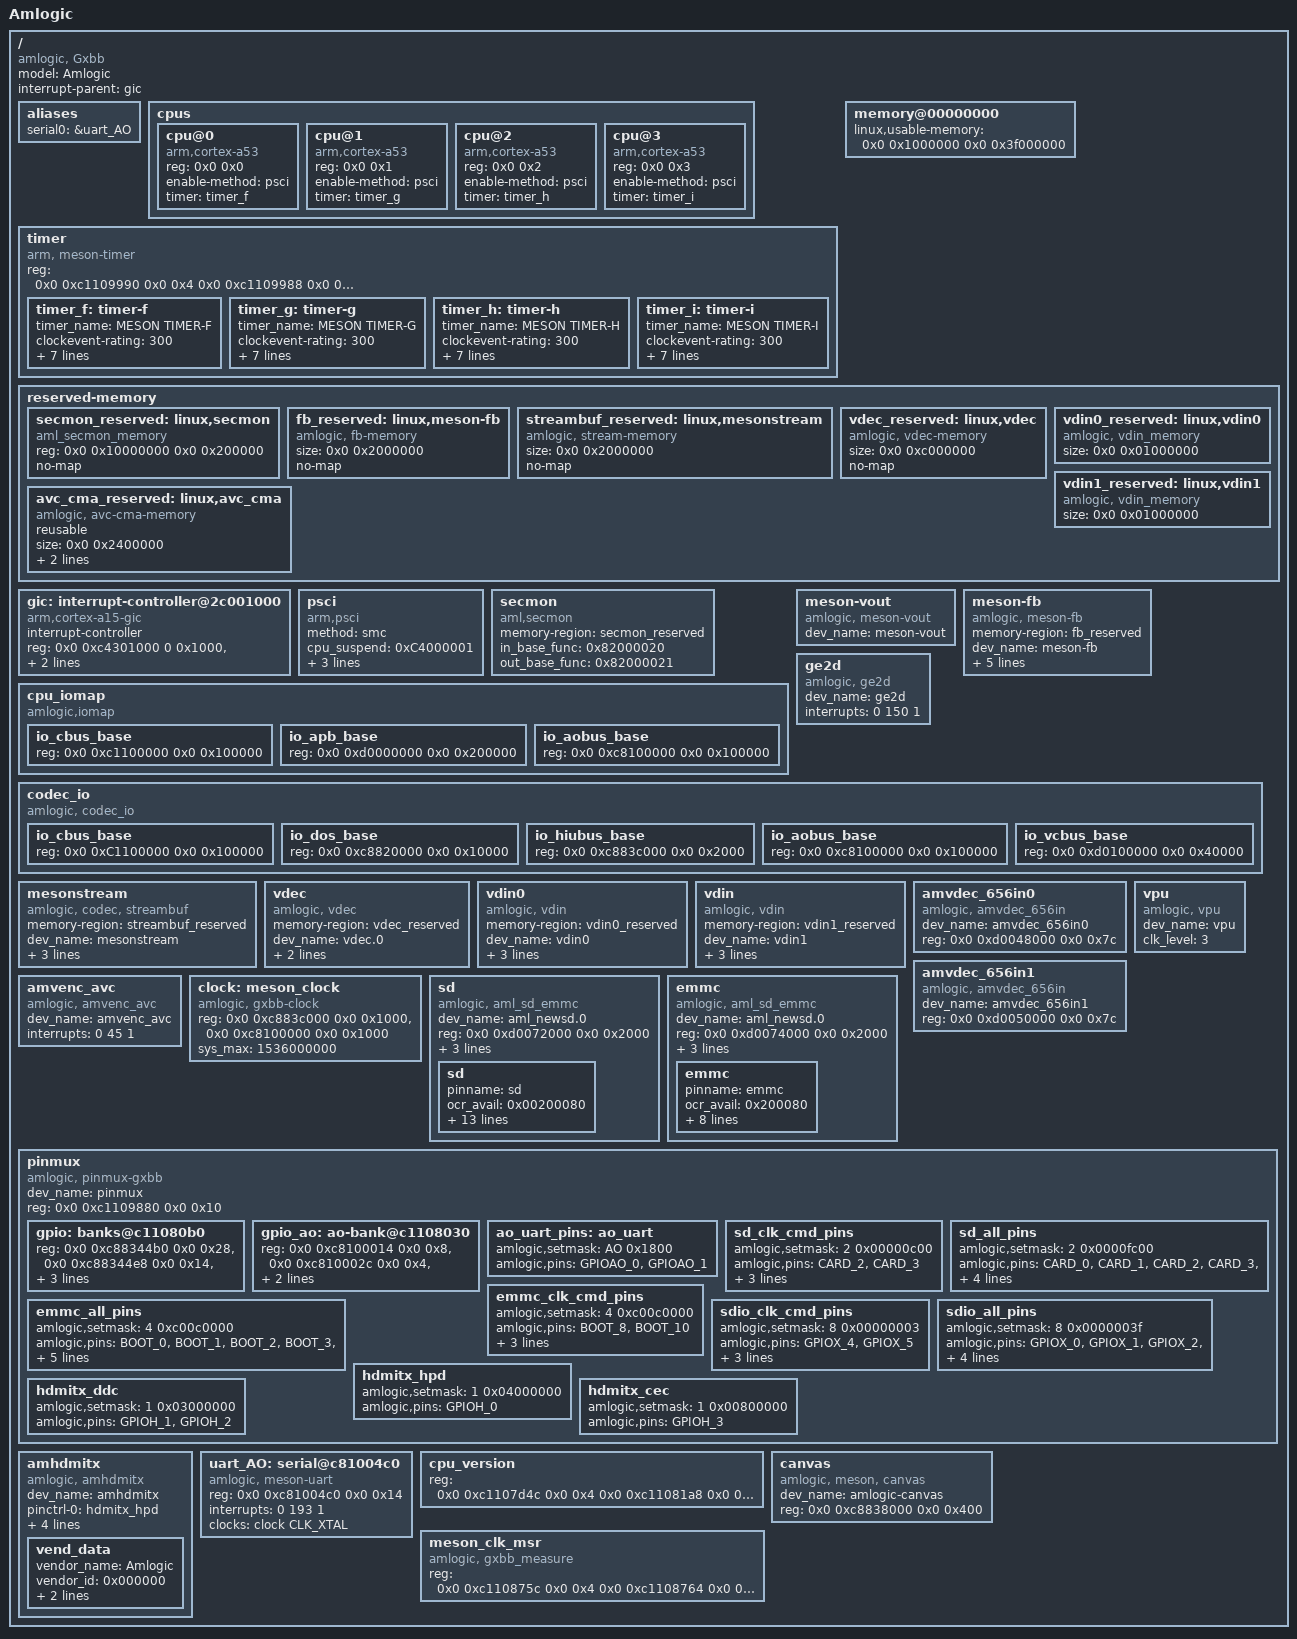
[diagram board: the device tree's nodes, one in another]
/*
 * Amlogic Ltd. GXBaby Plaform
 *
 */

/dts-v1/;

#include <dt-bindings/interrupt-controller/arm-gic.h>
#include <dt-bindings/clock/gxbb.h>
#include <dt-bindings/gpio/gxbb.h>
#include <dt-bindings/gpio/gpio.h>
#include <dt-bindings/reset/aml_gxbb.h>
/ {
	model = "Amlogic";
	compatible = "amlogic, Gxbb";
	interrupt-parent = <&gic>;
	#address-cells = <2>;
	#size-cells = <2>;

	aliases {
		serial0 = &uart_AO;
	};


	cpus {
		#address-cells = <2>;
		#size-cells = <0>;

		cpu@0 {
			device_type = "cpu";
			compatible = "arm,cortex-a53","arm,armv8";
			reg = <0x0 0x0>;
			enable-method = "psci";
			timer=<&timer_f>;
		};

		cpu@1 {
			device_type = "cpu";
			compatible = "arm,cortex-a53","arm,armv8";
			reg = <0x0 0x1>;
			enable-method = "psci";
			timer=<&timer_g>;
		};
		cpu@2 {
			device_type = "cpu";
			compatible = "arm,cortex-a53","arm,armv8";
			reg = <0x0 0x2>;
			enable-method = "psci";
			timer=<&timer_h>;
		};

		cpu@3 {
			device_type = "cpu";
			compatible = "arm,cortex-a53","arm,armv8";
			reg = <0x0 0x3>;
			enable-method = "psci";
			timer=<&timer_i>;
		};


	};
	timer{
		compatible = "arm, meson-timer";
		#address-cells = <2>;
		#size-cells = <2>;
		ranges;
		reg=   <0x0 0xc1109990 0x0 0x4 0x0 0xc1109988 0x0 0x4>;
		timer_f:timer-f{
			timer_name="MESON TIMER-F";
			clockevent-rating=<300>;
			clockevent-shift=<20>;
			clockevent-features=<0x03>;
			interrupts = <0 60 0>;
			bit_enable=<16>;
			bit_mode=<12>;
			bit_resolution=<0>;
			reg=   <0x0 0xc1109994 0x0 0x4>;
		};
		timer_g:timer-g{
			timer_name="MESON TIMER-G";
			clockevent-rating=<300>;
			clockevent-shift=<20>;
			clockevent-features=<0x03>;
			interrupts = <0 61 0>;
			bit_enable=<17>;
			bit_mode=<13>;
			bit_resolution=<2>;
			reg=<0x0 0xc1109998 0x0 0x4>;
		};
		timer_h:timer-h{
			timer_name="MESON TIMER-H";
			clockevent-rating=<300>;
			clockevent-shift=<20>;
			clockevent-features=<0x03>;
			interrupts = <0 62 0>;
			bit_enable=<18>;
			bit_mode=<14>;
			bit_resolution=<4>;
			reg=<0x0 0xc110999c 0x0 0x4>;
		};
		timer_i:timer-i{
			timer_name="MESON TIMER-I";
			clockevent-rating=<300>;
			clockevent-shift=<20>;
			clockevent-features=<0x03>;
			interrupts = <0 63 0>;
			bit_enable=<19>;
			bit_mode=<15>;
			bit_resolution=<6>;
			reg=<0x0 0xc11099a0 0x0 0x4>;
		};
	};

	memory@00000000 {
		device_type = "memory";
		linux,usable-memory = <0x0 0x1000000 0x0 0x3f000000>;
	};

	reserved-memory {
		#address-cells = <2>;
		#size-cells = <2>;
		ranges;
		/* global autoconfigured region for contiguous allocations */
		secmon_reserved:linux,secmon {
			compatible = "aml_secmon_memory";
			reg = <0x0 0x10000000 0x0 0x200000>;
			no-map;
		};

		fb_reserved:linux,meson-fb {
			compatible = "amlogic, fb-memory";
			size = <0x0 0x2000000>;
			no-map;
		};

		/*  DISP&MM-A/V stream */
		streambuf_reserved:linux,mesonstream {
			compatible = "amlogic, stream-memory";
			size = <0x0 0x2000000>;
			no-map;
		};

		/*  DISP&MM-A/V stream */
		vdec_reserved:linux,vdec {
			compatible = "amlogic, vdec-memory";
			size = <0x0 0xc000000>;
			no-map;
		};
		/*  vdin0 */
		vdin0_reserved:linux,vdin0 {
			compatible = "amlogic, vdin_memory";
			/* 1920x1080x2x4  =17M */
			size = <0x0 0x01000000>;
		};
		 /*  vdin1 */
		vdin1_reserved:linux,vdin1 {
			compatible = "amlogic, vdin_memory";
			/* 1920x1080x2x4  =17M */
			size = <0x0 0x01000000>;
		};

		/* AVC Encode CMA pool */
		avc_cma_reserved:linux,avc_cma {
			compatible = "amlogic, avc-cma-memory";
			reusable;
			size = <0x0 0x2400000>;
			alignment = <0x0 0x400000>;
			linux,contiguous-region;
		};
	};

	gic: interrupt-controller@2c001000 {
		compatible = "arm,cortex-a15-gic", "arm,cortex-a9-gic";
		#interrupt-cells = <3>;
		#address-cells = <0>;
		interrupt-controller;
		reg = <0x0 0xc4301000 0 0x1000>,
		      <0x0 0xc4302000 0 0x0100>;
		interrupts = <GIC_PPI 9 0xf04>;
	};




	psci {
		compatible = "arm,psci";
		method = "smc";
		cpu_suspend = <0xC4000001>;
		cpu_off = <0x84000002>;
		cpu_on = <0xC4000003>;
		migrate = <0xC4000005>;
	};
	secmon {
		compatible = "aml,secmon";
		memory-region = <&secmon_reserved>;
		in_base_func = <0x82000020>;
		out_base_func = <0x82000021>;
	};
	cpu_iomap{
		compatible = "amlogic,iomap";
		#address-cells=<2>;
		#size-cells=<2>;
		ranges;
		io_cbus_base{
			reg = <0x0 0xc1100000 0x0 0x100000>;
		};
		io_apb_base{
			reg = <0x0 0xd0000000 0x0 0x200000>;
		};
		io_aobus_base{
			reg = <0x0 0xc8100000 0x0 0x100000>;
		};
	};
	meson-vout {
		compatible = "amlogic, meson-vout";
		dev_name = "meson-vout";
		status = "okay";
	};
	meson-fb {
		compatible = "amlogic, meson-fb";
		memory-region = <&fb_reserved>;
		dev_name = "meson-fb";
		status = "okay";
		interrupts = <0 3 1
			0 89 1>;
		interrupt-names = "viu-vsync", "rdma";
		mem_size = <0x01800000 0x00100000>; /* fb0/fb1 memory size */
		vmode = <3>; /** 0:VMODE_720P 1:VMODE_LCD 2:VMODE_LVDS_1080P 3:VMODE_1080P */
		scale_mode = <1>; /** 0:VPU free scale 1:OSD free scale 2:OSD super scale */
		display_size_default = <1920 1080 1920 3240 32>; //1920*1080*4*3 = 0x17BB000
	};
	ge2d {
		compatible = "amlogic, ge2d";
		dev_name = "ge2d";
		status = "okay";
		interrupts = <0 150 1>;
		interrupt-names = "ge2d";
		/*
		resets = <&clock GCLK_IDX_GE2D>;
		reset-names = "ge2d";
		*/
	};
	codec_io {
		compatible = "amlogic, codec_io";
		#address-cells=<2>;
		#size-cells=<2>;
		ranges;
		io_cbus_base{
			reg = <0x0 0xC1100000 0x0 0x100000>;
		};
		io_dos_base{
			reg = <0x0 0xc8820000 0x0 0x10000>;
		};
		io_hiubus_base{
			reg = <0x0 0xc883c000 0x0 0x2000>;
		};
		io_aobus_base{
			reg = <0x0 0xc8100000 0x0 0x100000>;
		};
		io_vcbus_base{
			reg = <0x0 0xd0100000 0x0 0x40000>;
		};
	};
	mesonstream {
		compatible = "amlogic, codec, streambuf";
		memory-region = <&streambuf_reserved>;
		dev_name = "mesonstream";
		status = "okay";
		resets = <&clock GCLK_IDX_HIU_PARSER_TOP
			&clock GCLK_IDX_VPU_INTR
			&clock GCLK_IDX_DEMUX
			&clock GCLK_IDX_DOS>;
		reset-names = "parser_top",
			"vpu_intr",
			"demux",
			"vdec";
	};
	vdec {
		compatible = "amlogic, vdec";
		memory-region = <&vdec_reserved>;
		dev_name = "vdec.0";
		status = "okay";
		interrupts = <0 3 1
			0 23 1
			0 32 1
			0 43 1
			0 44 1
			0 45 1>;
		interrupt-names = "vsync",
			"demux",
			"parser",
			"mailbox_0",
			"mailbox_1",
			"mailbox_2";
	};
	vdin0 {
		compatible = "amlogic, vdin";
		memory-region = <&vdin0_reserved>;
		dev_name = "vdin0";
		status = "ok";
		reserve-iomap = "true";
		interrupts = <0 83 1>;
		vdin_id = <0>;
	};
	vdin {
		compatible = "amlogic, vdin";
		memory-region = <&vdin1_reserved>;
		dev_name = "vdin1";
		status = "ok";
		reserve-iomap = "true";
		interrupts = <0 85 1>;
		vdin_id = <1>;
	};
	amvdec_656in0 {
		compatible = "amlogic, amvdec_656in";
		dev_name = "amvdec_656in0";
		status = "ok";
		reg = <0x0 0xd0048000 0x0 0x7c>;
	};
	amvdec_656in1 {
		compatible = "amlogic, amvdec_656in";
		dev_name = "amvdec_656in1";
		status = "ok";
		reg = <0x0 0xd0050000 0x0 0x7c>;
	};

	amvenc_avc{
		compatible = "amlogic, amvenc_avc";
		//memory-region = <&amvenc_avc_reserved>;
		dev_name = "amvenc_avc";
		status = "okay";
		interrupts = <0 45 1>;
		interrupt-names = "mailbox_2";
	};

	clock: meson_clock {
		compatible = "amlogic, gxbb-clock";
		reg = <0x0 0xc883c000 0x0 0x1000>,   /* HIU BUS*/
		          <0x0 0xc8100000 0x0 0x1000>;   //AOBUS
		#clock-cells = <1>;
		#reset-cells = <1>;
		sys_max = <1536000000>;
	};

	vpu {
		compatible = "amlogic, vpu";
		dev_name = "vpu";
		status = "ok";
		clk_level = <3>;
		/**	0: 100.0M    1: 166.7M    2: 200.0M
			3: 250.0M    4: 333.3M    5: 400.0M
			6: 500.0M    7: 666.7M */
	};
    sd{
        compatible = "amlogic, aml_sd_emmc";
        dev_name = "aml_newsd.0";
        status = "okay";
        reg = <0x0 0xd0072000 0x0 0x2000>;
        interrupts = <	0 217 1
        				0 67 1
        				0 69 1>;
        pinctrl-names = "sd_clk_cmd_pins", "sd_all_pins";
        pinctrl-0 = <&sd_clk_cmd_pins>;
        pinctrl-1 = <&sd_all_pins>;
		sd{
	   		status = "okay";
	   		pinname = "sd";
	   		ocr_avail = <0x00200080>; // 3.3:0x200000, 1.8+3.3:0x00200080
	   		caps = "MMC_CAP_4_BIT_DATA","MMC_CAP_MMC_HIGHSPEED",
	   				"MMC_CAP_SD_HIGHSPEED","MMC_CAP_UHS_SDR12",
	   				"MMC_CAP_UHS_SDR25","MMC_CAP_UHS_SDR50",
	   				"MMC_CAP_UHS_SDR104";
	   		f_min = <400000>;
	   		f_max = <100000000>;
	   		max_req_size = <0x20000>;          /**128KB*/
			gpio_dat3 = <&gpio       CARD_4       GPIO_ACTIVE_HIGH>;
			jtag_pin =  <&gpio       CARD_0       GPIO_ACTIVE_HIGH>;
			gpio_cd =  <&gpio       CARD_6       GPIO_ACTIVE_HIGH>;
	   		irq_in = <3>;
	   		irq_out = <5>;
	   		card_type = <5>; /* 0:unknown, 1:mmc card(include eMMC), 2:sd card(include tSD), 3:sdio device(ie:sdio-wifi), 4:SD combo (IO+mem) card, 5:NON sdio device(means sd/mmc card), other:reserved */
		};
    };
    emmc{
        compatible = "amlogic, aml_sd_emmc";
        dev_name = "aml_newsd.0";
        status = "okay";
        reg = <0x0 0xd0074000 0x0 0x2000>;
        interrupts = <	0 218 1>;
        pinctrl-names = "emmc_clk_cmd_pins", "emmc_all_pins";
        pinctrl-0 = <&emmc_clk_cmd_pins>;
        pinctrl-1 = <&emmc_all_pins>;
        emmc{
            status = "okay";
            pinname = "emmc";
            ocr_avail = <0x200080>;          /**VDD voltage 3.3 ~ 3.4 */
            caps = "MMC_CAP_8_BIT_DATA","MMC_CAP_MMC_HIGHSPEED",
            		"MMC_CAP_SD_HIGHSPEED", "MMC_CAP_NONREMOVABLE"/*,
           		"MMC_CAP_ERASE", "MMC_CAP_HW_RESET"*/;
            //caps2 = "MMC_CAP2_HS200_1_8V_SDR";
			f_min = <400000>;
            f_max = <50000000>;
            max_req_size = <0x20000>;          /**256KB*/
//            gpio_dat3 = "BOOT_3"
		gpio_dat3 = <&gpio       BOOT_3      GPIO_ACTIVE_HIGH>;
            card_type = <1>; /* 1:mmc card(include eMMC), 2:sd card(include tSD), */
	};
    };
//    sdio{
//        compatible = "amlogic, aml_sd_emmc";
//        dev_name = "aml_newsd.0";
//        status = "okay";
//        reg = <0x0 0xd0070000 0x0 0x2000>;
//        interrupts = <	0 216 1>;
//        pinctrl-names =  "sdio_clk_cmd_pins", "sdio_all_pins";
//        pinctrl-0 = <&sdio_clk_cmd_pins>;
//        pinctrl-1 = <&sdio_all_pins>;
//        sdio{
//             status = "okay";
//             pinname = "sdio";
//             ocr_avail = <0x00200080>;  3.3:0x200000, 1.8+3.3:0x00200080
//             caps = "MMC_CAP_4_BIT_DATA","MMC_CAP_MMC_HIGHSPEED",
//             		"MMC_CAP_SD_HIGHSPEED", "MMC_CAP_NONREMOVABLE",
//             		"MMC_CAP_UHS_SDR12","MMC_CAP_UHS_SDR25",
//             		"MMC_CAP_UHS_SDR50","MMC_CAP_UHS_SDR104",
//             		"MMC_PM_KEEP_POWER";
//             f_min = <400000>;
//             f_max = <200000000>;
//             max_req_size = <0x20000>;          /**128KB*/
//             card_type = <3>;  /*3:sdio device(ie:sdio-wifi), 4:SD combo (IO+mem) card, */
//         };
//    };
	pinmux: pinmux{
		compatible = "amlogic, pinmux-gxbb";
		dev_name = "pinmux";
		#pinmux-cells=<2>;
		#address-cells = <2>;
		#size-cells = <2>;
		reg = <0x0 0xc1109880 0x0 0x10>;
		ranges;
		gpio: banks@c11080b0 {
			reg = <0x0 0xc88344b0 0x0 0x28>,
			<0x0 0xc88344e8 0x0 0x14>,
			<0x0 0xc8834120 0x0 0x14>,
			<0x0 0xc8834430 0x0 0x30>;
			reg-names = "mux", "pull", "pull-enable", "gpio";
			gpio-controller;
			#gpio-cells = <2>;
		};
		gpio_ao: ao-bank@c1108030 {
			reg = <0x0 0xc8100014 0x0 0x8>,
			<0x0 0xc810002c 0x0 0x4>,
			<0x0 0xc8100024 0x0 0x8>;
			reg-names = "mux", "pull", "gpio";
			gpio-controller;
			#gpio-cells = <2>;
		};
		ao_uart_pins:ao_uart{
			amlogic,setmask=<AO 0x1800>;
			amlogic,pins="GPIOAO_0", "GPIOAO_1";
		};
		sd_clk_cmd_pins:sd_clk_cmd_pins{
		    amlogic,setmask=<2 0x00000c00>;
		    amlogic,pins = "CARD_2","CARD_3"; /* CARD_2:CLK, CARD_3:CMD */
		    amlogic,enable-output=<1>; /* 0:output, 1:input */
		    amlogic,pullup=<1>;
		    amlogic,pullupen=<1>;
		};
		sd_all_pins:sd_all_pins{
		    amlogic,setmask=<2 0x0000fc00>;
		    amlogic,pins="CARD_0","CARD_1","CARD_2","CARD_3","CARD_4","CARD_5";
		    amlogic,enable-output=<1>; /* 0:output, 1:input */
		    amlogic,pullup=<1>;
		    amlogic,pullupen=<1>;
		};
		emmc_clk_cmd_pins:emmc_clk_cmd_pins{
		    amlogic,setmask=<4 0xc00c0000>;
		    amlogic,pins = "BOOT_8","BOOT_10"; /** BOOT_10:CMD, BOOT_8:CLK */
		    amlogic,enable-output=<1>; /** 0:output, 1:input */
		    amlogic,pullup=<1>;
		    amlogic,pullupen=<1>;
		};
		emmc_all_pins:emmc_all_pins{
		    amlogic,setmask=<4 0xc00c0000>;         /*sdhc c*/
		    amlogic,pins = "BOOT_0","BOOT_1","BOOT_2","BOOT_3","BOOT_4",
		    				"BOOT_5","BOOT_6","BOOT_7","BOOT_8","BOOT_10";
		    amlogic,enable-output=<1>; /** 0:output, 1:input */
		    amlogic,pullup=<1>;
		    amlogic,pullupen=<1>;
		};
		sdio_clk_cmd_pins:sdio_clk_cmd_pins{
		    amlogic,setmask=<8 0x00000003>;
		    amlogic,pins = "GPIOX_4","GPIOX_5"; /** GPIOX_5:CMD, GPIOX_4:CLK */
		    amlogic,enable-output=<1>; /** 0:output, 1:input */
		    amlogic,pullup=<1>;
		    amlogic,pullupen=<1>;
		};
		sdio_all_pins:sdio_all_pins{
		    amlogic,setmask=<8 0x0000003f>;
		    amlogic,pins = "GPIOX_0","GPIOX_1","GPIOX_2","GPIOX_3","GPIOX_4","GPIOX_5";
		    amlogic,enable-output=<1>; /** 0:output, 1:input */
		    amlogic,pullup=<1>;
		    amlogic,pullupen=<1>;
		};
		hdmitx_hpd: hdmitx_hpd {
			amlogic,setmask=<1 0x04000000>;
			amlogic,pins="GPIOH_0";
		};
		hdmitx_ddc: hdmitx_ddc {
			amlogic,setmask=<1 0x03000000>;
			amlogic,pins="GPIOH_1", "GPIOH_2";
		};
		hdmitx_cec: hdmitx_cec {
			amlogic,setmask=<1 0x00800000>;
			amlogic,pins="GPIOH_3";
		};
	};

	amhdmitx: amhdmitx{
		compatible = "amlogic, amhdmitx";
		dev_name = "amhdmitx";
		status = "okay";
		pinctrl-names="hdmitx_hpd", "hdmitx_ddc", "hdmitx_cec";
		pinctrl-0=<&hdmitx_hpd>;
		pinctrl-1=<&hdmitx_ddc>;
		pinctrl-2=<&hdmitx_cec>;
		vend-data = <&vend_data>;
		/* HPD, 57 + 32 = 89; CEC, 151 + 32 = 183*/
		interrupts = <0 57 1>, <0 151 1>;
		interrupt-names = "hdmitx_hpd", "hdmitx_cec";

		vend_data: vend_data{
			vendor_name = "Amlogic"; /* Max Chars: 8     */
			vendor_id = <0x000000>; /* Refer to http://standards.ieee.org/develop/regauth/oui/oui.txt   */
			product_desc = "GXBB Mbox"; /* Max Chars: 16    */
			cec_osd_string = "Amlogic MBox"; /* Max Chars: 14    */
		};
/*
		clocks = <&clock CLK_HDMITX_SYS &clock CLK_HDMITX_ENCP
			&clock CLK_HDMITX_ENCI &clock CLK_HDMITX_PIXEL
			&clock CLK_HDMITX_PHY>;
		clock-names = "hdmitx_clk_sys", "hdmitx_clk_encp",
		"hdmitx_clk_enci", "hdmitx_clk_pixel", "hdmitx_clk_phy";
*/
	};

	uart_AO: serial@c81004c0 {
		compatible = "amlogic, meson-uart";
		reg = <0x0 0xc81004c0 0x0 0x14>;
		interrupts = <0 193 1>;
		status = "okay";
		clocks = <&clock CLK_XTAL>;
		clock-names = "clk_uart";
	};

	cpu_version{
		reg=<0x0 0xc1107d4c 0x0 0x4
			0x0 0xc11081a8 0x0 0x4>;
	};

	canvas{
		compatible = "amlogic, meson, canvas";
		dev_name = "amlogic-canvas";
		status = "ok";
		reg = <0x0 0xc8838000 0x0 0x400>;
	};
	meson_clk_msr{
		compatible = "amlogic, gxbb_measure";
		reg = <0x0 0xc110875c 0x0 0x4
		       0x0 0xc1108764 0x0 0x4>;
	};

};
